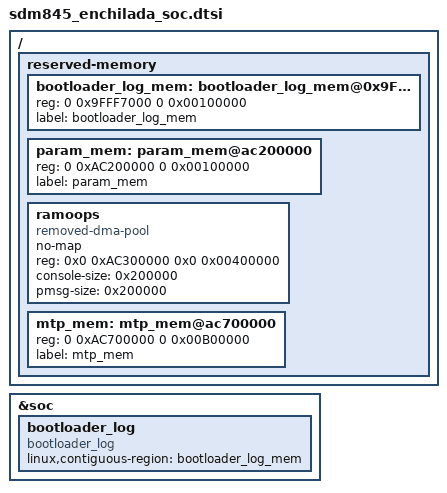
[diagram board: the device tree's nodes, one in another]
/* Copyright (c) 2016-2017, The Linux Foundation. All rights reserved.
 *
 * This program is free software; you can redistribute it and/or modify
 * it under the terms of the GNU General Public License version 2 and
 * only version 2 as published by the Free Software Foundation.
 *
 * This program is distributed in the hope that it will be useful,
 * but WITHOUT ANY WARRANTY; without even the implied warranty of
 * MERCHANTABILITY or FITNESS FOR A PARTICULAR PURPOSE.  See the
 * GNU General Public License for more details.
 */


/{
	reserved-memory {
		bootloader_log_mem: bootloader_log_mem@0x9FFF7000 {
			reg = <0 0x9FFF7000 0 0x00100000>;
			label = "bootloader_log_mem";
		};
		param_mem: param_mem@ac200000 {
			reg = <0 0xAC200000 0 0x00100000>;
			label = "param_mem";
		};
		ramoops {
			compatible = "removed-dma-pool", "ramoops";
			no-map;
			reg = <0x0 0xAC300000 0x0 0x00400000>;
			status = "ok";
			console-size = <0x200000>;
			pmsg-size = <0x200000>;
		};
		mtp_mem: mtp_mem@ac700000 {
			reg = <0 0xAC700000 0 0x00B00000>;
			label = "mtp_mem";
		};
	};
};

&soc {
bootloader_log {
	compatible = "bootloader_log";
	linux,contiguous-region = <&bootloader_log_mem>;
	};
};

